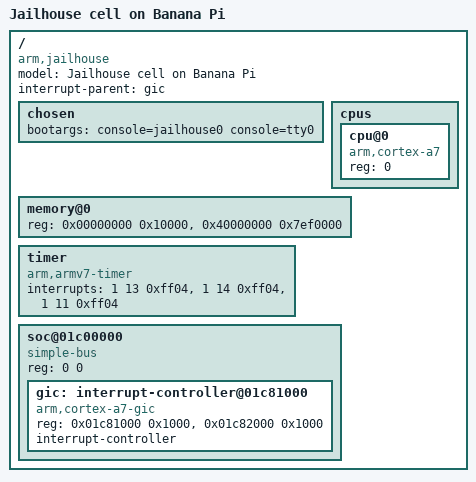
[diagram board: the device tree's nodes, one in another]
/dts-v1/;
/ {
	model = "Jailhouse cell on Banana Pi";
	compatible = "arm,jailhouse";

	#address-cells = <1>;
	#size-cells = <1>;

	interrupt-parent = <&gic>;

	chosen {
		bootargs = "console=jailhouse0 console=tty0";

		#address-cells = <1>;
		#size-cells = <1>;
		ranges;
	};

	cpus {
		#address-cells = <1>;
		#size-cells = <0>;

		cpu@0 {
			compatible = "arm,cortex-a7";
			device_type = "cpu";
			reg = <0>;
		};
	};

	memory@0 {
		device_type = "memory";
		reg = <0x00000000 0x10000>,
		      <0x40000000 0x7ef0000>;
	};

	timer {
		compatible = "arm,armv7-timer";
		interrupts = <1 13 0xff04>,
			     <1 14 0xff04>,
			     <1 11 0xff04>;
	};

	soc@01c00000 {
		compatible = "simple-bus";
		#address-cells = <1>;
		#size-cells = <1>;
		ranges;
		reg = <0 0>;

		gic: interrupt-controller@01c81000 {
			compatible = "arm,cortex-a7-gic", "arm,cortex-a15-gic";
			reg = <0x01c81000 0x1000>,
			      <0x01c82000 0x1000>;
			interrupt-controller;
			#interrupt-cells = <3>;
		};
	};
};
